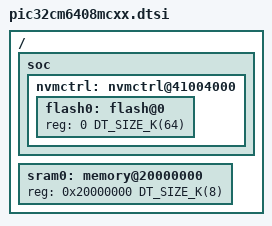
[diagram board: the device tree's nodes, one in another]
/*
 * Copyright (c) 2025 GP Orcullo
 *
 * SPDX-License-Identifier: Apache-2.0
 */

#include <mem.h>
#include <microchip/pic32cmmc.dtsi>

/ {
	soc {
		nvmctrl: nvmctrl@41004000  {
			flash0: flash@0 {
				reg = <0 DT_SIZE_K(64)>;
			};
		};
	};

	sram0: memory@20000000 {
		reg = <0x20000000 DT_SIZE_K(8)>;
	};
};
